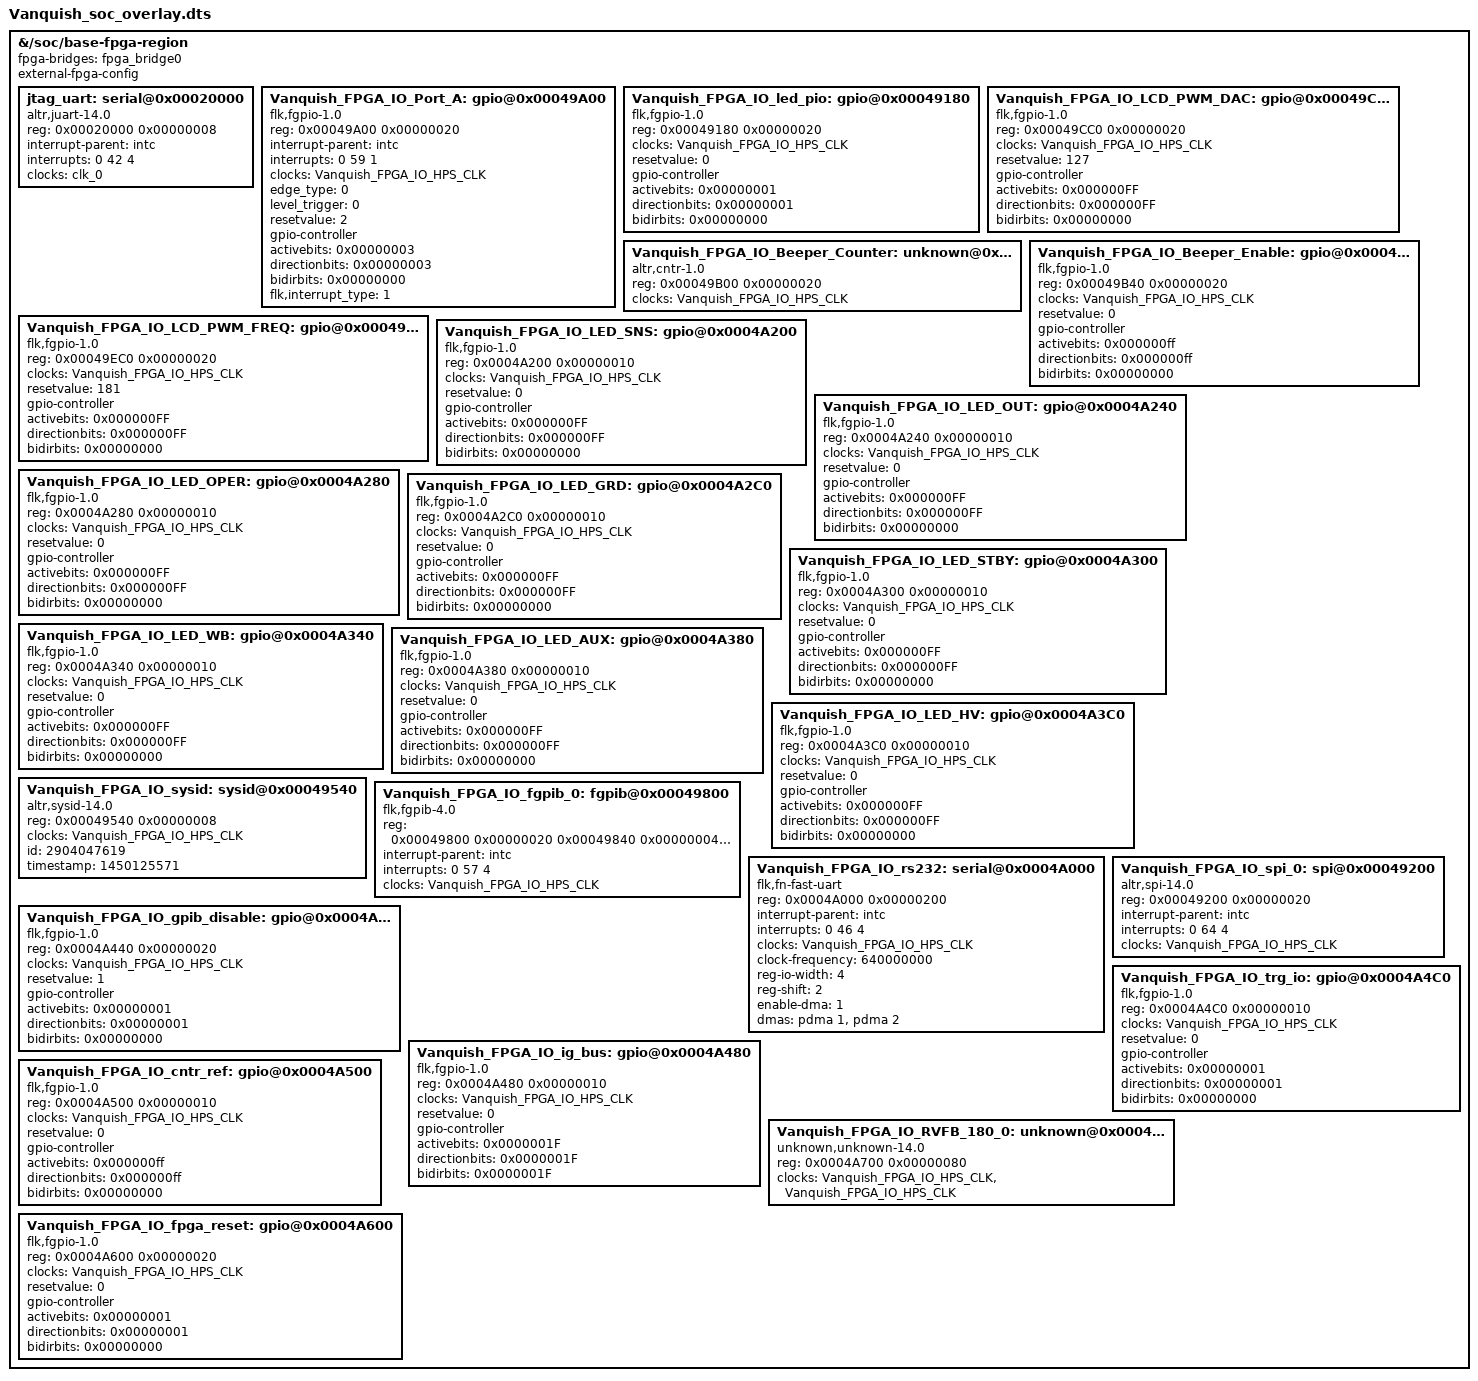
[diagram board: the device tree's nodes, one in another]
/*
 * Copyright Altera Corporation (C) 2015. All rights reserved.
 *
 * This program is free software; you can redistribute it and/or modify
 * it under the terms and conditions of the GNU General Public License,
 * version 2, as published by the Free Software Foundation.
 *
 * This program is distributed in the hope it will be useful, but WITHOUT
 * ANY WARRANTY; without even the implied warranty of MERCHANTABILITY or
 * FITNESS FOR A PARTICULAR PURPOSE.  See the GNU General Public License for
 * more details.
 *
 * You should have received a copy of the GNU General Public License along with
 * this program.  If not, see <http://www.gnu.org/licenses/>.
 */

 /dts-v1/ /plugin/;
/ {
	
	fragment@0 {
		target-path = "/soc/base-fpga-region";
		#address-cells = <1>;
		#size-cells = <1>;
		
		__overlay__ {
			#address-cells = <1>;
			#size-cells = <1>;
			ranges = <0 0xff200000 0x00200000>;
			fpga-bridges = <&fpga_bridge0>;
	
			external-fpga-config;			
			
			jtag_uart: serial@0x00020000 {
				compatible = "altr,juart-14.0", "altr,juart-1.0";
				reg = < 0x00020000 0x00000008 >;
				interrupt-parent = < &intc >;
				interrupts = < 0 42 4 >;
				clocks = < &clk_0 >;
			}; //end serial@0x100020000 (jtag_uart)

			Vanquish_FPGA_IO_Port_A: gpio@0x00049A00 {
				compatible = "flk,fgpio-1.0";	/* appended from boardinfo */
				reg = < 0x00049A00 0x00000020 >;
				interrupt-parent = < &intc >;
				interrupts = < 0 59 1 >;
				clocks = < &Vanquish_FPGA_IO_HPS_CLK >;
				edge_type = < 0 >;	/* embeddedsw.dts.params.edge_type type NUMBER */
				level_trigger = < 0 >;	/* embeddedsw.dts.params.level_trigger type NUMBER */
				resetvalue = < 2 >;	/* embeddedsw.dts.params.resetvalue type NUMBER */
				#gpio-cells = < 2 >;
				gpio-controller;
				activebits = < 0x00000003 >;	/* appended from boardinfo */
				directionbits = < 0x00000003 >;	/* appended from boardinfo */
				bidirbits = < 0x00000000 >;	/* appended from boardinfo */
				flk,interrupt_type = < 1 >;	/* appended from boardinfo */
			}; //end gpio@0x100049A00 (Vanquish_FPGA_IO_Port_A)

			Vanquish_FPGA_IO_led_pio: gpio@0x00049180 {
				compatible = "flk,fgpio-1.0";	/* appended from boardinfo */
				reg = < 0x00049180 0x00000020 >;
				clocks = < &Vanquish_FPGA_IO_HPS_CLK >;
				resetvalue = < 0 >;	/* embeddedsw.dts.params.resetvalue type NUMBER */
				#gpio-cells = < 2 >;
				gpio-controller;
				activebits = < 0x00000001 >;	/* appended from boardinfo */
				directionbits = < 0x00000001 >;	/* appended from boardinfo */
				bidirbits = < 0x00000000 >;	/* appended from boardinfo */
			}; //end gpio@0x100049180 (Vanquish_FPGA_IO_led_pio)

			Vanquish_FPGA_IO_LCD_PWM_DAC: gpio@0x00049CC0 {
				compatible = "flk,fgpio-1.0";	/* appended from boardinfo */
				reg = < 0x00049CC0 0x00000020 >;
				clocks = < &Vanquish_FPGA_IO_HPS_CLK >;
				resetvalue = < 127 >;	/* embeddedsw.dts.params.resetvalue type NUMBER */
				#gpio-cells = < 2 >;
				gpio-controller;
				activebits = < 0x000000FF >;	/* appended from boardinfo */
				directionbits = < 0x000000FF >;	/* appended from boardinfo */
				bidirbits = < 0x00000000 >;	/* appended from boardinfo */
			}; //end gpio@0x100049CC0 (Vanquish_FPGA_IO_LCD_PWM_DAC)

			Vanquish_FPGA_IO_Beeper_Counter: unknown@0x00049B00 {
				compatible = "altr,cntr-1.0";	/* appended from boardinfo */
				reg = < 0x00049B00 0x00000020 >;
				clocks = < &Vanquish_FPGA_IO_HPS_CLK >;
			}; //end unknown@0x100049B00 (Vanquish_FPGA_IO_Beeper_Counter)

			Vanquish_FPGA_IO_Beeper_Enable: gpio@0x00049B40 {
				compatible = "flk,fgpio-1.0";	/* appended from boardinfo */
				reg = < 0x00049B40 0x00000020 >;
				clocks = < &Vanquish_FPGA_IO_HPS_CLK >;
				resetvalue = < 0 >;	/* embeddedsw.dts.params.resetvalue type NUMBER */
				#gpio-cells = < 2 >;
				gpio-controller;
				activebits = < 0x000000ff >;	/* appended from boardinfo */
				directionbits = < 0x000000ff >;	/* appended from boardinfo */
				bidirbits = < 0x00000000 >;	/* appended from boardinfo */
			}; //end gpio@0x100049B40 (Vanquish_FPGA_IO_Beeper_Enable)

			Vanquish_FPGA_IO_LCD_PWM_FREQ: gpio@0x00049EC0 {
				compatible = "flk,fgpio-1.0";	/* appended from boardinfo */
				reg = < 0x00049EC0 0x00000020 >;
				clocks = < &Vanquish_FPGA_IO_HPS_CLK >;
				resetvalue = < 181 >;	/* embeddedsw.dts.params.resetvalue type NUMBER */
				#gpio-cells = < 2 >;
				gpio-controller;
				activebits = < 0x000000FF >;	/* appended from boardinfo */
				directionbits = < 0x000000FF >;	/* appended from boardinfo */
				bidirbits = < 0x00000000 >;	/* appended from boardinfo */
			}; //end gpio@0x100049EC0 (Vanquish_FPGA_IO_LCD_PWM_FREQ)

			Vanquish_FPGA_IO_LED_SNS: gpio@0x0004A200 {
				compatible = "flk,fgpio-1.0";	/* appended from boardinfo */
				reg = < 0x0004A200 0x00000010 >;
				clocks = < &Vanquish_FPGA_IO_HPS_CLK >;
				resetvalue = < 0 >;	/* embeddedsw.dts.params.resetvalue type NUMBER */
				#gpio-cells = < 2 >;
				gpio-controller;
				activebits = < 0x000000FF >;	/* appended from boardinfo */
				directionbits = < 0x000000FF >;	/* appended from boardinfo */
				bidirbits = < 0x00000000 >;	/* appended from boardinfo */
			}; //end gpio@0x10004A200 (Vanquish_FPGA_IO_LED_SNS)

			Vanquish_FPGA_IO_LED_OUT: gpio@0x0004A240 {
				compatible = "flk,fgpio-1.0";	/* appended from boardinfo */
				reg = < 0x0004A240 0x00000010 >;
				clocks = < &Vanquish_FPGA_IO_HPS_CLK >;
				resetvalue = < 0 >;	/* embeddedsw.dts.params.resetvalue type NUMBER */
				#gpio-cells = < 2 >;
				gpio-controller;
				activebits = < 0x000000FF >;	/* appended from boardinfo */
				directionbits = < 0x000000FF >;	/* appended from boardinfo */
				bidirbits = < 0x00000000 >;	/* appended from boardinfo */
			}; //end gpio@0x10004A240 (Vanquish_FPGA_IO_LED_OUT)

			Vanquish_FPGA_IO_LED_OPER: gpio@0x0004A280 {
				compatible = "flk,fgpio-1.0";	/* appended from boardinfo */
				reg = < 0x0004A280 0x00000010 >;
				clocks = < &Vanquish_FPGA_IO_HPS_CLK >;
				resetvalue = < 0 >;	/* embeddedsw.dts.params.resetvalue type NUMBER */
				#gpio-cells = < 2 >;
				gpio-controller;
				activebits = < 0x000000FF >;	/* appended from boardinfo */
				directionbits = < 0x000000FF >;	/* appended from boardinfo */
				bidirbits = < 0x00000000 >;	/* appended from boardinfo */
			}; //end gpio@0x10004A280 (Vanquish_FPGA_IO_LED_OPER)

			Vanquish_FPGA_IO_LED_GRD: gpio@0x0004A2C0 {
				compatible = "flk,fgpio-1.0";	/* appended from boardinfo */
				reg = < 0x0004A2C0 0x00000010 >;
				clocks = < &Vanquish_FPGA_IO_HPS_CLK >;
				resetvalue = < 0 >;	/* embeddedsw.dts.params.resetvalue type NUMBER */
				#gpio-cells = < 2 >;
				gpio-controller;
				activebits = < 0x000000FF >;	/* appended from boardinfo */
				directionbits = < 0x000000FF >;	/* appended from boardinfo */
				bidirbits = < 0x00000000 >;	/* appended from boardinfo */
			}; //end gpio@0x10004A2C0 (Vanquish_FPGA_IO_LED_GRD)

			Vanquish_FPGA_IO_LED_STBY: gpio@0x0004A300 {
				compatible = "flk,fgpio-1.0";	/* appended from boardinfo */
				reg = < 0x0004A300 0x00000010 >;
				clocks = < &Vanquish_FPGA_IO_HPS_CLK >;
				resetvalue = < 0 >;	/* embeddedsw.dts.params.resetvalue type NUMBER */
				#gpio-cells = < 2 >;
				gpio-controller;
				activebits = < 0x000000FF >;	/* appended from boardinfo */
				directionbits = < 0x000000FF >;	/* appended from boardinfo */
				bidirbits = < 0x00000000 >;	/* appended from boardinfo */
			}; //end gpio@0x10004A300 (Vanquish_FPGA_IO_LED_STBY)

			Vanquish_FPGA_IO_LED_WB: gpio@0x0004A340 {
				compatible = "flk,fgpio-1.0";	/* appended from boardinfo */
				reg = < 0x0004A340 0x00000010 >;
				clocks = < &Vanquish_FPGA_IO_HPS_CLK >;
				resetvalue = < 0 >;	/* embeddedsw.dts.params.resetvalue type NUMBER */
				#gpio-cells = < 2 >;
				gpio-controller;
				activebits = < 0x000000FF >;	/* appended from boardinfo */
				directionbits = < 0x000000FF >;	/* appended from boardinfo */
				bidirbits = < 0x00000000 >;	/* appended from boardinfo */
			}; //end gpio@0x10004A340 (Vanquish_FPGA_IO_LED_WB)

			Vanquish_FPGA_IO_LED_AUX: gpio@0x0004A380 {
				compatible = "flk,fgpio-1.0";	/* appended from boardinfo */
				reg = < 0x0004A380 0x00000010 >;
				clocks = < &Vanquish_FPGA_IO_HPS_CLK >;
				resetvalue = < 0 >;	/* embeddedsw.dts.params.resetvalue type NUMBER */
				#gpio-cells = < 2 >;
				gpio-controller;
				activebits = < 0x000000FF >;	/* appended from boardinfo */
				directionbits = < 0x000000FF >;	/* appended from boardinfo */
				bidirbits = < 0x00000000 >;	/* appended from boardinfo */
			}; //end gpio@0x10004A380 (Vanquish_FPGA_IO_LED_AUX)

			Vanquish_FPGA_IO_LED_HV: gpio@0x0004A3C0 {
				compatible = "flk,fgpio-1.0";	/* appended from boardinfo */
				reg = < 0x0004A3C0 0x00000010 >;
				clocks = < &Vanquish_FPGA_IO_HPS_CLK >;
				resetvalue = < 0 >;	/* embeddedsw.dts.params.resetvalue type NUMBER */
				#gpio-cells = < 2 >;
				gpio-controller;
				activebits = < 0x000000FF >;	/* appended from boardinfo */
				directionbits = < 0x000000FF >;	/* appended from boardinfo */
				bidirbits = < 0x00000000 >;	/* appended from boardinfo */
			}; //end gpio@0x10004A3C0 (Vanquish_FPGA_IO_LED_HV)

			Vanquish_FPGA_IO_sysid: sysid@0x00049540 {
				compatible = "altr,sysid-14.0", "altr,sysid-1.0";
				reg = < 0x00049540 0x00000008 >;
				clocks = < &Vanquish_FPGA_IO_HPS_CLK >;
				id = < 2904047619 >;	/* embeddedsw.dts.params.id type NUMBER */
				timestamp = < 1450125571 >;	/* embeddedsw.dts.params.timestamp type NUMBER */
			}; //end sysid@0x100049540 (Vanquish_FPGA_IO_sysid)

			Vanquish_FPGA_IO_fgpib_0: fgpib@0x00049800 {
				compatible = "flk,fgpib-4.0";
				reg = < 0x00049800 0x00000020 
					0x00049840 0x00000004 
					0x00049880 0x00000004 >;
				reg-names = "s0", "s1", "s2";
				interrupt-parent = < &intc >;
				interrupts = < 0 57 4 >;
				clocks = < &Vanquish_FPGA_IO_HPS_CLK >;
			}; //end fgpib@0x100049800 (Vanquish_FPGA_IO_fgpib_0)

			Vanquish_FPGA_IO_rs232: serial@0x0004A000 {
				compatible = "flk,fn-fast-uart";
				reg = < 0x0004A000 0x00000200 >;
				interrupt-parent = < &intc >;
				interrupts = < 0 46 4 >;
				clocks = < &Vanquish_FPGA_IO_HPS_CLK >;
				clock-frequency = < 640000000 >;	/* this is BS but the Linux serial core assumes the max baud rate is this clock freq divided by 16. */
				reg-io-width = < 4 >;	/* embeddedsw.dts.params.reg-io-width type NUMBER */
				reg-shift = < 2 >;	/* embeddedsw.dts.params.reg-shift type NUMBER */
				enable-dma = < 1 >;	/* appended from boardinfo */
				dmas = <&pdma 1 &pdma 2>;
				dma-names = "tx", "rx";
			}; //end serial@0x10004A000 (Vanquish_FPGA_IO_rs232)

			Vanquish_FPGA_IO_spi_0: spi@0x00049200 {
				compatible = "altr,spi-14.0", "altr,spi-1.0";
				reg = < 0x00049200 0x00000020 >;
				interrupt-parent = < &intc >;
				interrupts = < 0 64 4 >;
				clocks = < &Vanquish_FPGA_IO_HPS_CLK >;
			}; //end spi@0x100049200 (Vanquish_FPGA_IO_spi_0)

			Vanquish_FPGA_IO_gpib_disable: gpio@0x0004A440 {
				compatible = "flk,fgpio-1.0";	/* appended from boardinfo */
				reg = < 0x0004A440 0x00000020 >;
				clocks = < &Vanquish_FPGA_IO_HPS_CLK >;
				resetvalue = < 1 >;	/* embeddedsw.dts.params.resetvalue type NUMBER */
				#gpio-cells = < 2 >;
				gpio-controller;
				activebits = < 0x00000001 >;	/* appended from boardinfo */
				directionbits = < 0x00000001 >;	/* appended from boardinfo */
				bidirbits = < 0x00000000 >;	/* appended from boardinfo */
			}; //end gpio@0x10004A440 (Vanquish_FPGA_IO_gpib_disable)

			Vanquish_FPGA_IO_ig_bus: gpio@0x0004A480 {
				compatible = "flk,fgpio-1.0";	/* appended from boardinfo */
				reg = < 0x0004A480 0x00000010 >;
				clocks = < &Vanquish_FPGA_IO_HPS_CLK >;
				resetvalue = < 0 >;	/* embeddedsw.dts.params.resetvalue type NUMBER */
				#gpio-cells = < 2 >;
				gpio-controller;
				activebits = < 0x0000001F >;	/* appended from boardinfo */
				directionbits = < 0x0000001F >;	/* appended from boardinfo */
				bidirbits = < 0x0000001F >;	/* appended from boardinfo */
			}; //end gpio@0x10004A480 (Vanquish_FPGA_IO_ig_bus)

			Vanquish_FPGA_IO_trg_io: gpio@0x0004A4C0 {
				compatible = "flk,fgpio-1.0";	/* appended from boardinfo */
				reg = < 0x0004A4C0 0x00000010 >;
				clocks = < &Vanquish_FPGA_IO_HPS_CLK >;
				resetvalue = < 0 >;	/* embeddedsw.dts.params.resetvalue type NUMBER */
				#gpio-cells = < 2 >;
				gpio-controller;
				activebits = < 0x00000001 >;	/* appended from boardinfo */
				directionbits = < 0x00000001 >;	/* appended from boardinfo */
				bidirbits = < 0x00000000 >;	/* appended from boardinfo */
			}; //end gpio@0x10004A4C0 (Vanquish_FPGA_IO_trg_io)

			Vanquish_FPGA_IO_cntr_ref: gpio@0x0004A500 {
				compatible = "flk,fgpio-1.0";	/* appended from boardinfo */
				reg = < 0x0004A500 0x00000010 >;
				clocks = < &Vanquish_FPGA_IO_HPS_CLK >;
				resetvalue = < 0 >;	/* embeddedsw.dts.params.resetvalue type NUMBER */
				#gpio-cells = < 2 >;
				gpio-controller;
				activebits = < 0x000000ff >;	/* appended from boardinfo */
				directionbits = < 0x000000ff >;	/* appended from boardinfo */
				bidirbits = < 0x00000000 >;	/* appended from boardinfo */
			}; //end gpio@0x10004A500 (Vanquish_FPGA_IO_cntr_ref)

			Vanquish_FPGA_IO_RVFB_180_0: unknown@0x0004A700 {
				compatible = "unknown,unknown-14.0";
				reg = < 0x0004A700 0x00000080 >;
				clocks = < &Vanquish_FPGA_IO_HPS_CLK &Vanquish_FPGA_IO_HPS_CLK >;
				clock-names = "avs_clock", "clk";
			}; //end unknown@0x10004A700 (Vanquish_FPGA_IO_RVFB_180_0)

			Vanquish_FPGA_IO_fpga_reset: gpio@0x0004A600 {
				compatible = "flk,fgpio-1.0";	/* appended from boardinfo */
				reg = < 0x0004A600 0x00000020 >;
				clocks = < &Vanquish_FPGA_IO_HPS_CLK >;
				resetvalue = < 0 >;	/* embeddedsw.dts.params.resetvalue type NUMBER */
				#gpio-cells = < 2 >;
				gpio-controller;
				activebits = < 0x00000001 >;	/* appended from boardinfo */
				directionbits = < 0x00000001 >;	/* appended from boardinfo */
				bidirbits = < 0x00000000 >;	/* appended from boardinfo */
			}; //end gpio@0x10004A600 (Vanquish_FPGA_IO_fpga_reset)		
				 
		};

	};
};
